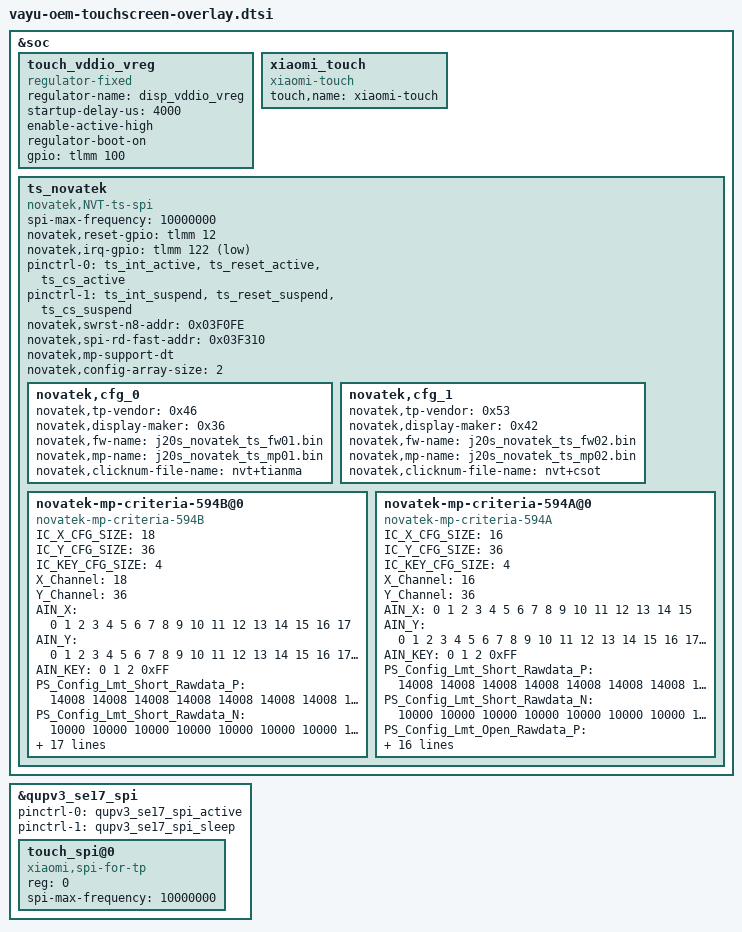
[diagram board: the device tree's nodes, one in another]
/* Copyright (c) 2021, The Linux Foundation. All rights reserved.
*  Copyright (c) 2021, Jebaitedneko <Jebaitedneko@gmail.com>.
*
* This program is free software; you can redistribute it and/or modify
* it under the terms of the GNU General Public License version 2 and
* only version 2 as published by the Free Software Foundation.
*
* This program is distributed in the hope that it will be useful,
* but WITHOUT ANY WARRANTY; without even the implied warranty of
* MERCHANTABILITY or FITNESS FOR A PARTICULAR PURPOSE.  See the
* GNU General Public License for more details.
*/

&soc {
	touch_vddio_vreg: touch_vddio_vreg {
		compatible = "regulator-fixed";
		regulator-name = "disp_vddio_vreg";
		startup-delay-us = <4000>;
		enable-active-high;
		regulator-boot-on;
		gpio = <&tlmm 100 0>;
	 };
	xiaomi_touch {
		compatible = "xiaomi-touch";
		status = "ok";
		touch,name = "xiaomi-touch";
	};

};

&qupv3_se17_spi {
		pinctrl-0 = <&qupv3_se17_spi_active>;
		pinctrl-1 = <&qupv3_se17_spi_sleep>;
		status = "ok";
		touch_spi@0 {
				compatible = "xiaomi,spi-for-tp";
				reg = <0>;
				status = "ok";
				spi-max-frequency = <10000000>;  //10M
		};
};

/* Novatek device tree node */
&soc {
	ts_novatek {
		compatible = "novatek,NVT-ts-spi";
		status = "ok";
		spi-max-frequency = <10000000>;  /*4800000,9600000,15000000,19200000 10M*/
		novatek,reset-gpio = <&tlmm 12 0x00>;
		novatek,irq-gpio = <&tlmm 122 0x2001>;
		pinctrl-names = "pmx_ts_active", "pmx_ts_suspend";
		pinctrl-0 = <&ts_int_active &ts_reset_active &ts_cs_active>;
		pinctrl-1 = <&ts_int_suspend &ts_reset_suspend &ts_cs_suspend>;
		/* 672 */
		/*novatek,swrst-n8-addr = <0x01F01A>;*/
		/* 672A */
		novatek,swrst-n8-addr = <0x03F0FE>;
		novatek,spi-rd-fast-addr = <0x03F310>;
		/* MP */
		novatek,mp-support-dt;
		novatek,config-array-size = <2>;
		novatek,cfg_0 {
			novatek,tp-vendor = <0x46>;
			novatek,display-maker = <0x36>;
			novatek,fw-name = "j20s_novatek_ts_fw01.bin";
			novatek,mp-name = "j20s_novatek_ts_mp01.bin";
			novatek,clicknum-file-name = "nvt+tianma";
		};
		novatek,cfg_1 {
			novatek,tp-vendor = <0x53>;
			novatek,display-maker = <0x42>;
			novatek,fw-name = "j20s_novatek_ts_fw02.bin";
			novatek,mp-name = "j20s_novatek_ts_mp02.bin";
			novatek,clicknum-file-name = "nvt+csot";
		};
		/* for Xiaomi J20S 672C CSOT6.67" module */
		novatek-mp-criteria-594B@0 {
			#address-cells = <1>;
			#size-cells = <0>;
			compatible = "novatek-mp-criteria-594B";
			/* MP Config */
			IC_X_CFG_SIZE = <18>;
			IC_Y_CFG_SIZE = <36>;
			IC_KEY_CFG_SIZE = <4>;
			X_Channel = <18>;
			Y_Channel = <36>;
			AIN_X = <0 1 2 3 4 5 6 7 8 9 10 11 12 13 14 15 16 17>;
			AIN_Y = <0 1 2 3 4 5 6 7 8 9 10 11 12 13 14 15 16 17
						18 19 20 21 22 23 24 25 26 27 28 29 30 31 32 33 34 35>;
			AIN_KEY = <0 1 2 0xFF>;
			/* MP Criteria */
			PS_Config_Lmt_Short_Rawdata_P = <
				14008 14008 14008 14008 14008 14008 14008 14008 14008 14008 14008 14008 14008 14008 14008 14008 14008 14008
				14008 14008 14008 14008 14008 14008 14008 14008 14008 14008 14008 14008 14008 14008 14008 14008 14008 14008
				14008 14008 14008 14008 14008 14008 14008 14008 14008 14008 14008 14008 14008 14008 14008 14008 14008 14008
				14008 14008 14008 14008 14008 14008 14008 14008 14008 14008 14008 14008 14008 14008 14008 14008 14008 14008
				14008 14008 14008 14008 14008 14008 14008 14008 14008 14008 14008 14008 14008 14008 14008 14008 14008 14008
				14008 14008 14008 14008 14008 14008 14008 14008 14008 14008 14008 14008 14008 14008 14008 14008 14008 14008
				14008 14008 14008 14008 14008 14008 14008 14008 14008 14008 14008 14008 14008 14008 14008 14008 14008 14008
				14008 14008 14008 14008 14008 14008 14008 14008 14008 14008 14008 14008 14008 14008 14008 14008 14008 14008
				14008 14008 14008 14008 14008 14008 14008 14008 14008 14008 14008 14008 14008 14008 14008 14008 14008 14008
				14008 14008 14008 14008 14008 14008 14008 14008 14008 14008 14008 14008 14008 14008 14008 14008 14008 14008
				14008 14008 14008 14008 14008 14008 14008 14008 14008 14008 14008 14008 14008 14008 14008 14008 14008 14008
				14008 14008 14008 14008 14008 14008 14008 14008 14008 14008 14008 14008 14008 14008 14008 14008 14008 14008
				14008 14008 14008 14008 14008 14008 14008 14008 14008 14008 14008 14008 14008 14008 14008 14008 14008 14008
				14008 14008 14008 14008 14008 14008 14008 14008 14008 14008 14008 14008 14008 14008 14008 14008 14008 14008
				14008 14008 14008 14008 14008 14008 14008 14008 14008 14008 14008 14008 14008 14008 14008 14008 14008 14008
				14008 14008 14008 14008 14008 14008 14008 14008 14008 14008 14008 14008 14008 14008 14008 14008 14008 14008
				14008 14008 14008 14008 14008 14008 14008 14008 14008 14008 14008 14008 14008 14008 14008 14008 14008 14008
				14008 14008 14008 14008 14008 14008 14008 14008 14008 14008 14008 14008 14008 14008 14008 14008 14008 14008
				14008 14008 14008 14008 14008 14008 14008 14008 14008 14008 14008 14008 14008 14008 14008 14008 14008 14008
				14008 14008 14008 14008 14008 14008 14008 14008 14008 14008 14008 14008 14008 14008 14008 14008 14008 14008
				14008 14008 14008 14008 14008 14008 14008 14008 14008 14008 14008 14008 14008 14008 14008 14008 14008 14008
				14008 14008 14008 14008 14008 14008 14008 14008 14008 14008 14008 14008 14008 14008 14008 14008 14008 14008
				14008 14008 14008 14008 14008 14008 14008 14008 14008 14008 14008 14008 14008 14008 14008 14008 14008 14008
				14008 14008 14008 14008 14008 14008 14008 14008 14008 14008 14008 14008 14008 14008 14008 14008 14008 14008
				14008 14008 14008 14008 14008 14008 14008 14008 14008 14008 14008 14008 14008 14008 14008 14008 14008 14008
				14008 14008 14008 14008 14008 14008 14008 14008 14008 14008 14008 14008 14008 14008 14008 14008 14008 14008
				14008 14008 14008 14008 14008 14008 14008 14008 14008 14008 14008 14008 14008 14008 14008 14008 14008 14008
				14008 14008 14008 14008 14008 14008 14008 14008 14008 14008 14008 14008 14008 14008 14008 14008 14008 14008
				14008 14008 14008 14008 14008 14008 14008 14008 14008 14008 14008 14008 14008 14008 14008 14008 14008 14008
				14008 14008 14008 14008 14008 14008 14008 14008 14008 14008 14008 14008 14008 14008 14008 14008 14008 14008
				14008 14008 14008 14008 14008 14008 14008 14008 14008 14008 14008 14008 14008 14008 14008 14008 14008 14008
				14008 14008 14008 14008 14008 14008 14008 14008 14008 14008 14008 14008 14008 14008 14008 14008 14008 14008
				14008 14008 14008 14008 14008 14008 14008 14008 14008 14008 14008 14008 14008 14008 14008 14008 14008 14008
				14008 14008 14008 14008 14008 14008 14008 14008 14008 14008 14008 14008 14008 14008 14008 14008 14008 14008
				14008 14008 14008 14008 14008 14008 14008 14008 14008 14008 14008 14008 14008 14008 14008 14008 14008 14008
				14008 14008 14008 14008 14008 14008 14008 14008 14008 14008 14008 14008 14008 14008 14008 14008 14008 14008
				14008 14008 14008>;

			PS_Config_Lmt_Short_Rawdata_N = <
				10000 10000 10000 10000 10000 10000 10000 10000 10000 10000 10000 10000 10000 10000 10000 10000 10000 10000
				10000 10000 10000 10000 10000 10000 10000 10000 10000 10000 10000 10000 10000 10000 10000 10000 10000 10000
				10000 10000 10000 10000 10000 10000 10000 10000 10000 10000 10000 10000 10000 10000 10000 10000 10000 10000
				10000 10000 10000 10000 10000 10000 10000 10000 10000 10000 10000 10000 10000 10000 10000 10000 10000 10000
				10000 10000 10000 10000 10000 10000 10000 10000 10000 10000 10000 10000 10000 10000 10000 10000 10000 10000
				10000 10000 10000 10000 10000 10000 10000 10000 10000 10000 10000 10000 10000 10000 10000 10000 10000 10000
				10000 10000 10000 10000 10000 10000 10000 10000 10000 10000 10000 10000 10000 10000 10000 10000 10000 10000
				10000 10000 10000 10000 10000 10000 10000 10000 10000 10000 10000 10000 10000 10000 10000 10000 10000 10000
				10000 10000 10000 10000 10000 10000 10000 10000 10000 10000 10000 10000 10000 10000 10000 10000 10000 10000
				10000 10000 10000 10000 10000 10000 10000 10000 10000 10000 10000 10000 10000 10000 10000 10000 10000 10000
				10000 10000 10000 10000 10000 10000 10000 10000 10000 10000 10000 10000 10000 10000 10000 10000 10000 10000
				10000 10000 10000 10000 10000 10000 10000 10000 10000 10000 10000 10000 10000 10000 10000 10000 10000 10000
				10000 10000 10000 10000 10000 10000 10000 10000 10000 10000 10000 10000 10000 10000 10000 10000 10000 10000
				10000 10000 10000 10000 10000 10000 10000 10000 10000 10000 10000 10000 10000 10000 10000 10000 10000 10000
				10000 10000 10000 10000 10000 10000 10000 10000 10000 10000 10000 10000 10000 10000 10000 10000 10000 10000
				10000 10000 10000 10000 10000 10000 10000 10000 10000 10000 10000 10000 10000 10000 10000 10000 10000 10000
				10000 10000 10000 10000 10000 10000 10000 10000 10000 10000 10000 10000 10000 10000 10000 10000 10000 10000
				10000 10000 10000 10000 10000 10000 10000 10000 10000 10000 10000 10000 10000 10000 10000 10000 10000 10000
				10000 10000 10000 10000 10000 10000 10000 10000 10000 10000 10000 10000 10000 10000 10000 10000 10000 10000
				10000 10000 10000 10000 10000 10000 10000 10000 10000 10000 10000 10000 10000 10000 10000 10000 10000 10000
				10000 10000 10000 10000 10000 10000 10000 10000 10000 10000 10000 10000 10000 10000 10000 10000 10000 10000
				10000 10000 10000 10000 10000 10000 10000 10000 10000 10000 10000 10000 10000 10000 10000 10000 10000 10000
				10000 10000 10000 10000 10000 10000 10000 10000 10000 10000 10000 10000 10000 10000 10000 10000 10000 10000
				10000 10000 10000 10000 10000 10000 10000 10000 10000 10000 10000 10000 10000 10000 10000 10000 10000 10000
				10000 10000 10000 10000 10000 10000 10000 10000 10000 10000 10000 10000 10000 10000 10000 10000 10000 10000
				10000 10000 10000 10000 10000 10000 10000 10000 10000 10000 10000 10000 10000 10000 10000 10000 10000 10000
				10000 10000 10000 10000 10000 10000 10000 10000 10000 10000 10000 10000 10000 10000 10000 10000 10000 10000
				10000 10000 10000 10000 10000 10000 10000 10000 10000 10000 10000 10000 10000 10000 10000 10000 10000 10000
				10000 10000 10000 10000 10000 10000 10000 10000 10000 10000 10000 10000 10000 10000 10000 10000 10000 10000
				10000 10000 10000 10000 10000 10000 10000 10000 10000 10000 10000 10000 10000 10000 10000 10000 10000 10000
				10000 10000 10000 10000 10000 10000 10000 10000 10000 10000 10000 10000 10000 10000 10000 10000 10000 10000
				10000 10000 10000 10000 10000 10000 10000 10000 10000 10000 10000 10000 10000 10000 10000 10000 10000 10000
				10000 10000 10000 10000 10000 10000 10000 10000 10000 10000 10000 10000 10000 10000 10000 10000 10000 10000
				10000 10000 10000 10000 10000 10000 10000 10000 10000 10000 10000 10000 10000 10000 10000 10000 10000 10000
				10000 10000 10000 10000 10000 10000 10000 10000 10000 10000 10000 10000 10000 10000 10000 10000 10000 10000
				10000 10000 10000 10000 10000 10000 10000 10000 10000 10000 10000 10000 10000 10000 10000 10000 10000 10000
				10000 10000 10000>;

			PS_Config_Lmt_Open_Rawdata_P = <
				5120 5120 5120 5120 5120 5120 5120 5120 5120 5120 5120 5120 5120 5120 5120 5120 5120 5120
				5120 5120 5120 5120 5120 5120 5120 5120 5120 5120 5120 5120 5120 5120 5120 5120 5120 5120
				5120 5120 5120 5120 5120 5120 5120 5120 5120 5120 5120 5120 5120 5120 5120 5120 5120 5120
				5120 5120 5120 5120 5120 5120 5120 5120 5120 5120 5120 5120 5120 5120 5120 5120 5120 5120
				5120 5120 5120 5120 5120 5120 5120 5120 5120 5120 5120 5120 5120 5120 5120 5120 5120 5120
				5120 5120 5120 5120 5120 5120 5120 5120 5120 5120 5120 5120 5120 5120 5120 5120 5120 5120
				5120 5120 5120 5120 5120 5120 5120 5120 5120 5120 5120 5120 5120 5120 5120 5120 5120 5120
				5120 5120 5120 5120 5120 5120 5120 5120 5120 5120 5120 5120 5120 5120 5120 5120 5120 5120
				5120 5120 5120 5120 5120 5120 5120 5120 5120 5120 5120 5120 5120 5120 5120 5120 5120 5120
				5120 5120 5120 5120 5120 5120 5120 5120 5120 5120 5120 5120 5120 5120 5120 5120 5120 5120
				5120 5120 5120 5120 5120 5120 5120 5120 5120 5120 5120 5120 5120 5120 5120 5120 5120 5120
				5120 5120 5120 5120 5120 5120 5120 5120 5120 5120 5120 5120 5120 5120 5120 5120 5120 5120
				5120 5120 5120 5120 5120 5120 5120 5120 5120 5120 5120 5120 5120 5120 5120 5120 5120 5120
				5120 5120 5120 5120 5120 5120 5120 5120 5120 5120 5120 5120 5120 5120 5120 5120 5120 5120
				5120 5120 5120 5120 5120 5120 5120 5120 5120 5120 5120 5120 5120 5120 5120 5120 5120 5120
				5120 5120 5120 5120 5120 5120 5120 5120 5120 5120 5120 5120 5120 5120 5120 5120 5120 5120
				5120 5120 5120 5120 5120 5120 5120 5120 5120 5120 5120 5120 5120 5120 5120 5120 5120 5120
				5120 5120 5120 5120 5120 5120 5120 5120 5120 5120 5120 5120 5120 5120 5120 5120 5120 5120
				5120 5120 5120 5120 5120 5120 5120 5120 5120 5120 5120 5120 5120 5120 5120 5120 5120 5120
				5120 5120 5120 5120 5120 5120 5120 5120 5120 5120 5120 5120 5120 5120 5120 5120 5120 5120
				5120 5120 5120 5120 5120 5120 5120 5120 5120 5120 5120 5120 5120 5120 5120 5120 5120 5120
				5120 5120 5120 5120 5120 5120 5120 5120 5120 5120 5120 5120 5120 5120 5120 5120 5120 5120
				5120 5120 5120 5120 5120 5120 5120 5120 5120 5120 5120 5120 5120 5120 5120 5120 5120 5120
				5120 5120 5120 5120 5120 5120 5120 5120 5120 5120 5120 5120 5120 5120 5120 5120 5120 5120
				5120 5120 5120 5120 5120 5120 5120 5120 5120 5120 5120 5120 5120 5120 5120 5120 5120 5120
				5120 5120 5120 5120 5120 5120 5120 5120 5120 5120 5120 5120 5120 5120 5120 5120 5120 5120
				5120 5120 5120 5120 5120 5120 5120 5120 5120 5120 5120 5120 5120 5120 5120 5120 5120 5120
				5120 5120 5120 5120 5120 5120 5120 5120 5120 5120 5120 5120 5120 5120 5120 5120 5120 5120
				5120 5120 5120 5120 5120 5120 5120 5120 5120 5120 5120 5120 5120 5120 5120 5120 5120 5120
				5120 5120 5120 5120 5120 5120 5120 5120 5120 5120 5120 5120 5120 5120 5120 5120 5120 5120
				5120 5120 5120 5120 5120 5120 5120 5120 5120 5120 5120 5120 5120 5120 5120 5120 5120 5120
				5120 5120 5120 5120 5120 5120 5120 5120 5120 5120 5120 5120 5120 5120 5120 5120 5120 5120
				5120 5120 5120 5120 5120 5120 5120 5120 5120 5120 5120 5120 5120 5120 5120 5120 5120 5120
				5120 5120 5120 5120 5120 5120 5120 5120 5120 5120 5120 5120 5120 5120 5120 5120 5120 5120
				5120 5120 5120 5120 5120 5120 5120 5120 5120 5120 5120 5120 5120 5120 5120 5120 5120 5120
				5120 5120 5120 5120 5120 5120 5120 5120 5120 5120 5120 5120 5120 5120 5120 5120 5120 5120
				5120 5120 5120>;

			PS_Config_Lmt_Open_Rawdata_N = <
				(-511) (-511) (-511) (-511) (-511) (-511) (-511) (-511) (-511) (-511) (-511) (-511) (-511) (-511) (-511) (-511) (-511) (-511)
				(-511) (-511) (-511) (-511) (-511) (-511) (-511) (-511) (-511) (-511) (-511) (-511) (-511) (-511) (-511) (-511) (-511) (-511)
				(-511) (-511) (-511) (-511) (-511) (-511) (-511) (-511) (-511) (-511) (-511) (-511) (-511) (-511) (-511) (-511) (-511) (-511)
				(-511) (-511) (-511) (-511) (-511) (-511) (-511) (-511) (-511) (-511) (-511) (-511) (-511) (-511) (-511) (-511) (-511) (-511)
				(-511) (-511) (-511) (-511) (-511) (-511) (-511) (-511) (-511) (-511) (-511) (-511) (-511) (-511) (-511) (-511) (-511) (-511)
				(-511) (-511) (-511) (-511) (-511) (-511) (-511) (-511) (-511) (-511) (-511) (-511) (-511) (-511) (-511) (-511) (-511) (-511)
				(-511) (-511) (-511) (-511) (-511) (-511) (-511) (-511) (-511) (-511) (-511) (-511) (-511) (-511) (-511) (-511) (-511) (-511)
				(-511) (-511) (-511) (-511) (-511) (-511) (-511) (-511) (-511) (-511) (-511) (-511) (-511) (-511) (-511) (-511) (-511) (-511)
				(-511) (-511) (-511) (-511) (-511) (-511) (-511) (-511) (-511) (-511) (-511) (-511) (-511) (-511) (-511) (-511) (-511) (-511)
				(-511) (-511) (-511) (-511) (-511) (-511) (-511) (-511) (-511) (-511) (-511) (-511) (-511) (-511) (-511) (-511) (-511) (-511)
				(-511) (-511) (-511) (-511) (-511) (-511) (-511) (-511) (-511) (-511) (-511) (-511) (-511) (-511) (-511) (-511) (-511) (-511)
				(-511) (-511) (-511) (-511) (-511) (-511) (-511) (-511) (-511) (-511) (-511) (-511) (-511) (-511) (-511) (-511) (-511) (-511)
				(-511) (-511) (-511) (-511) (-511) (-511) (-511) (-511) (-511) (-511) (-511) (-511) (-511) (-511) (-511) (-511) (-511) (-511)
				(-511) (-511) (-511) (-511) (-511) (-511) (-511) (-511) (-511) (-511) (-511) (-511) (-511) (-511) (-511) (-511) (-511) (-511)
				(-511) (-511) (-511) (-511) (-511) (-511) (-511) (-511) (-511) (-511) (-511) (-511) (-511) (-511) (-511) (-511) (-511) (-511)
				(-511) (-511) (-511) (-511) (-511) (-511) (-511) (-511) (-511) (-511) (-511) (-511) (-511) (-511) (-511) (-511) (-511) (-511)
				(-511) (-511) (-511) (-511) (-511) (-511) (-511) (-511) (-511) (-511) (-511) (-511) (-511) (-511) (-511) (-511) (-511) (-511)
				(-511) (-511) (-511) (-511) (-511) (-511) (-511) (-511) (-511) (-511) (-511) (-511) (-511) (-511) (-511) (-511) (-511) (-511)
				(-511) (-511) (-511) (-511) (-511) (-511) (-511) (-511) (-511) (-511) (-511) (-511) (-511) (-511) (-511) (-511) (-511) (-511)
				(-511) (-511) (-511) (-511) (-511) (-511) (-511) (-511) (-511) (-511) (-511) (-511) (-511) (-511) (-511) (-511) (-511) (-511)
				(-511) (-511) (-511) (-511) (-511) (-511) (-511) (-511) (-511) (-511) (-511) (-511) (-511) (-511) (-511) (-511) (-511) (-511)
				(-511) (-511) (-511) (-511) (-511) (-511) (-511) (-511) (-511) (-511) (-511) (-511) (-511) (-511) (-511) (-511) (-511) (-511)
				(-511) (-511) (-511) (-511) (-511) (-511) (-511) (-511) (-511) (-511) (-511) (-511) (-511) (-511) (-511) (-511) (-511) (-511)
				(-511) (-511) (-511) (-511) (-511) (-511) (-511) (-511) (-511) (-511) (-511) (-511) (-511) (-511) (-511) (-511) (-511) (-511)
				(-511) (-511) (-511) (-511) (-511) (-511) (-511) (-511) (-511) (-511) (-511) (-511) (-511) (-511) (-511) (-511) (-511) (-511)
				(-511) (-511) (-511) (-511) (-511) (-511) (-511) (-511) (-511) (-511) (-511) (-511) (-511) (-511) (-511) (-511) (-511) (-511)
				(-511) (-511) (-511) (-511) (-511) (-511) (-511) (-511) (-511) (-511) (-511) (-511) (-511) (-511) (-511) (-511) (-511) (-511)
				(-511) (-511) (-511) (-511) (-511) (-511) (-511) (-511) (-511) (-511) (-511) (-511) (-511) (-511) (-511) (-511) (-511) (-511)
				(-511) (-511) (-511) (-511) (-511) (-511) (-511) (-511) (-511) (-511) (-511) (-511) (-511) (-511) (-511) (-511) (-511) (-511)
				(-511) (-511) (-511) (-511) (-511) (-511) (-511) (-511) (-511) (-511) (-511) (-511) (-511) (-511) (-511) (-511) (-511) (-511)
				(-511) (-511) (-511) (-511) (-511) (-511) (-511) (-511) (-511) (-511) (-511) (-511) (-511) (-511) (-511) (-511) (-511) (-511)
				(-511) (-511) (-511) (-511) (-511) (-511) (-511) (-511) (-511) (-511) (-511) (-511) (-511) (-511) (-511) (-511) (-511) (-511)
				(-511) (-511) (-511) (-511) (-511) (-511) (-511) (-511) (-511) (-511) (-511) (-511) (-511) (-511) (-511) (-511) (-511) (-511)
				(-511) (-511) (-511) (-511) (-511) (-511) (-511) (-511) (-511) (-511) (-511) (-511) (-511) (-511) (-511) (-511) (-511) (-511)
				(-511) (-511) (-511) (-511) (-511) (-511) (-511) (-511) (-511) (-511) (-511) (-511) (-511) (-511) (-511) (-511) (-511) (-511)
				(-511) (-511) (-511) (-511) (-511) (-511) (-511) (-511) (-511) (-511) (-511) (-511) (-511) (-511) (-511) (-511) (-511) (-511)
				(-511) (-511) (-511)>;

			PS_Config_Lmt_FW_Rawdata_P = <
				3840 3840 3840 3840 3840 3840 3840 3840 3840 3840 3840 3840 3840 3840 3840 3840 3840 3840
				3840 3840 3840 3840 3840 3840 3840 3840 3840 3840 3840 3840 3840 3840 3840 3840 3840 3840
				3840 3840 3840 3840 3840 3840 3840 3840 3840 3840 3840 3840 3840 3840 3840 3840 3840 3840
				3840 3840 3840 3840 3840 3840 3840 3840 3840 3840 3840 3840 3840 3840 3840 3840 3840 3840
				3840 3840 3840 3840 3840 3840 3840 3840 3840 3840 3840 3840 3840 3840 3840 3840 3840 3840
				3840 3840 3840 3840 3840 3840 3840 3840 3840 3840 3840 3840 3840 3840 3840 3840 3840 3840
				3840 3840 3840 3840 3840 3840 3840 3840 3840 3840 3840 3840 3840 3840 3840 3840 3840 3840
				3840 3840 3840 3840 3840 3840 3840 3840 3840 3840 3840 3840 3840 3840 3840 3840 3840 3840
				3840 3840 3840 3840 3840 3840 3840 3840 3840 3840 3840 3840 3840 3840 3840 3840 3840 3840
				3840 3840 3840 3840 3840 3840 3840 3840 3840 3840 3840 3840 3840 3840 3840 3840 3840 3840
				3840 3840 3840 3840 3840 3840 3840 3840 3840 3840 3840 3840 3840 3840 3840 3840 3840 3840
				3840 3840 3840 3840 3840 3840 3840 3840 3840 3840 3840 3840 3840 3840 3840 3840 3840 3840
				3840 3840 3840 3840 3840 3840 3840 3840 3840 3840 3840 3840 3840 3840 3840 3840 3840 3840
				3840 3840 3840 3840 3840 3840 3840 3840 3840 3840 3840 3840 3840 3840 3840 3840 3840 3840
				3840 3840 3840 3840 3840 3840 3840 3840 3840 3840 3840 3840 3840 3840 3840 3840 3840 3840
				3840 3840 3840 3840 3840 3840 3840 3840 3840 3840 3840 3840 3840 3840 3840 3840 3840 3840
				3840 3840 3840 3840 3840 3840 3840 3840 3840 3840 3840 3840 3840 3840 3840 3840 3840 3840
				3840 3840 3840 3840 3840 3840 3840 3840 3840 3840 3840 3840 3840 3840 3840 3840 3840 3840
				3840 3840 3840 3840 3840 3840 3840 3840 3840 3840 3840 3840 3840 3840 3840 3840 3840 3840
				3840 3840 3840 3840 3840 3840 3840 3840 3840 3840 3840 3840 3840 3840 3840 3840 3840 3840
				3840 3840 3840 3840 3840 3840 3840 3840 3840 3840 3840 3840 3840 3840 3840 3840 3840 3840
				3840 3840 3840 3840 3840 3840 3840 3840 3840 3840 3840 3840 3840 3840 3840 3840 3840 3840
				3840 3840 3840 3840 3840 3840 3840 3840 3840 3840 3840 3840 3840 3840 3840 3840 3840 3840
				3840 3840 3840 3840 3840 3840 3840 3840 3840 3840 3840 3840 3840 3840 3840 3840 3840 3840
				3840 3840 3840 3840 3840 3840 3840 3840 3840 3840 3840 3840 3840 3840 3840 3840 3840 3840
				3840 3840 3840 3840 3840 3840 3840 3840 3840 3840 3840 3840 3840 3840 3840 3840 3840 3840
				3840 3840 3840 3840 3840 3840 3840 3840 3840 3840 3840 3840 3840 3840 3840 3840 3840 3840
				3840 3840 3840 3840 3840 3840 3840 3840 3840 3840 3840 3840 3840 3840 3840 3840 3840 3840
				3840 3840 3840 3840 3840 3840 3840 3840 3840 3840 3840 3840 3840 3840 3840 3840 3840 3840
				3840 3840 3840 3840 3840 3840 3840 3840 3840 3840 3840 3840 3840 3840 3840 3840 3840 3840
				3840 3840 3840 3840 3840 3840 3840 3840 3840 3840 3840 3840 3840 3840 3840 3840 3840 3840
				3840 3840 3840 3840 3840 3840 3840 3840 3840 3840 3840 3840 3840 3840 3840 3840 3840 3840
				3840 3840 3840 3840 3840 3840 3840 3840 3840 3840 3840 3840 3840 3840 3840 3840 3840 3840
				3840 3840 3840 3840 3840 3840 3840 3840 3840 3840 3840 3840 3840 3840 3840 3840 3840 3840
				3840 3840 3840 3840 3840 3840 3840 3840 3840 3840 3840 3840 3840 3840 3840 3840 3840 3840
				3840 3840 3840 3840 3840 3840 3840 3840 3840 3840 3840 3840 3840 3840 3840 3840 3840 3840
				3840 3840 3840>;

			PS_Config_Lmt_FW_Rawdata_N = <
				240 240 240 240 240 240 240 240 240 240 240 240 240 240 240 240 240 240
				240 240 240 240 240 240 240 240 240 240 240 240 240 240 240 240 240 240
				240 240 240 240 240 240 240 240 240 240 240 240 240 240 240 240 240 240
				240 240 240 240 240 240 240 240 240 240 240 240 240 240 240 240 240 240
				240 240 240 240 240 240 240 240 240 240 240 240 240 240 240 240 240 240
				240 240 240 240 240 240 240 240 240 240 240 240 240 240 240 240 240 240
				240 240 240 240 240 240 240 240 240 240 240 240 240 240 240 240 240 240
				240 240 240 240 240 240 240 240 240 240 240 240 240 240 240 240 240 240
				240 240 240 240 240 240 240 240 240 240 240 240 240 240 240 240 240 240
				240 240 240 240 240 240 240 240 240 240 240 240 240 240 240 240 240 240
				240 240 240 240 240 240 240 240 240 240 240 240 240 240 240 240 240 240
				240 240 240 240 240 240 240 240 240 240 240 240 240 240 240 240 240 240
				240 240 240 240 240 240 240 240 240 240 240 240 240 240 240 240 240 240
				240 240 240 240 240 240 240 240 240 240 240 240 240 240 240 240 240 240
				240 240 240 240 240 240 240 240 240 240 240 240 240 240 240 240 240 240
				240 240 240 240 240 240 240 240 240 240 240 240 240 240 240 240 240 240
				240 240 240 240 240 240 240 240 240 240 240 240 240 240 240 240 240 240
				240 240 240 240 240 240 240 240 240 240 240 240 240 240 240 240 240 240
				240 240 240 240 240 240 240 240 240 240 240 240 240 240 240 240 240 240
				240 240 240 240 240 240 240 240 240 240 240 240 240 240 240 240 240 240
				240 240 240 240 240 240 240 240 240 240 240 240 240 240 240 240 240 240
				240 240 240 240 240 240 240 240 240 240 240 240 240 240 240 240 240 240
				240 240 240 240 240 240 240 240 240 240 240 240 240 240 240 240 240 240
				240 240 240 240 240 240 240 240 240 240 240 240 240 240 240 240 240 240
				240 240 240 240 240 240 240 240 240 240 240 240 240 240 240 240 240 240
				240 240 240 240 240 240 240 240 240 240 240 240 240 240 240 240 240 240
				240 240 240 240 240 240 240 240 240 240 240 240 240 240 240 240 240 240
				240 240 240 240 240 240 240 240 240 240 240 240 240 240 240 240 240 240
				240 240 240 240 240 240 240 240 240 240 240 240 240 240 240 240 240 240
				240 240 240 240 240 240 240 240 240 240 240 240 240 240 240 240 240 240
				240 240 240 240 240 240 240 240 240 240 240 240 240 240 240 240 240 240
				240 240 240 240 240 240 240 240 240 240 240 240 240 240 240 240 240 240
				240 240 240 240 240 240 240 240 240 240 240 240 240 240 240 240 240 240
				240 240 240 240 240 240 240 240 240 240 240 240 240 240 240 240 240 240
				240 240 240 240 240 240 240 240 240 240 240 240 240 240 240 240 240 240
				240 240 240 240 240 240 240 240 240 240 240 240 240 240 240 240 240 240
				240 240 240>;

			PS_Config_Lmt_FW_CC_P = <
				314 314 314 314 314 314 314 314 314 314 314 314 314 314 314 314 314 314
				314 314 314 314 314 314 314 314 314 314 314 314 314 314 314 314 314 314
				314 314 314 314 314 314 314 314 314 314 314 314 314 314 314 314 314 314
				314 314 314 314 314 314 314 314 314 314 314 314 314 314 314 314 314 314
				314 314 314 314 314 314 314 314 314 314 314 314 314 314 314 314 314 314
				314 314 314 314 314 314 314 314 314 314 314 314 314 314 314 314 314 314
				314 314 314 314 314 314 314 314 314 314 314 314 314 314 314 314 314 314
				314 314 314 314 314 314 314 314 314 314 314 314 314 314 314 314 314 314
				314 314 314 314 314 314 314 314 314 314 314 314 314 314 314 314 314 314
				314 314 314 314 314 314 314 314 314 314 314 314 314 314 314 314 314 314
				314 314 314 314 314 314 314 314 314 314 314 314 314 314 314 314 314 314
				314 314 314 314 314 314 314 314 314 314 314 314 314 314 314 314 314 314
				314 314 314 314 314 314 314 314 314 314 314 314 314 314 314 314 314 314
				314 314 314 314 314 314 314 314 314 314 314 314 314 314 314 314 314 314
				314 314 314 314 314 314 314 314 314 314 314 314 314 314 314 314 314 314
				314 314 314 314 314 314 314 314 314 314 314 314 314 314 314 314 314 314
				314 314 314 314 314 314 314 314 314 314 314 314 314 314 314 314 314 314
				314 314 314 314 314 314 314 314 314 314 314 314 314 314 314 314 314 314
				314 314 314 314 314 314 314 314 314 314 314 314 314 314 314 314 314 314
				314 314 314 314 314 314 314 314 314 314 314 314 314 314 314 314 314 314
				314 314 314 314 314 314 314 314 314 314 314 314 314 314 314 314 314 314
				314 314 314 314 314 314 314 314 314 314 314 314 314 314 314 314 314 314
				314 314 314 314 314 314 314 314 314 314 314 314 314 314 314 314 314 314
				314 314 314 314 314 314 314 314 314 314 314 314 314 314 314 314 314 314
				314 314 314 314 314 314 314 314 314 314 314 314 314 314 314 314 314 314
				314 314 314 314 314 314 314 314 314 314 314 314 314 314 314 314 314 314
				314 314 314 314 314 314 314 314 314 314 314 314 314 314 314 314 314 314
				314 314 314 314 314 314 314 314 314 314 314 314 314 314 314 314 314 314
				314 314 314 314 314 314 314 314 314 314 314 314 314 314 314 314 314 314
				314 314 314 314 314 314 314 314 314 314 314 314 314 314 314 314 314 314
				314 314 314 314 314 314 314 314 314 314 314 314 314 314 314 314 314 314
				314 314 314 314 314 314 314 314 314 314 314 314 314 314 314 314 314 314
				314 314 314 314 314 314 314 314 314 314 314 314 314 314 314 314 314 314
				314 314 314 314 314 314 314 314 314 314 314 314 314 314 314 314 314 314
				314 314 314 314 314 314 314 314 314 314 314 314 314 314 314 314 314 314
				314 314 314 314 314 314 314 314 314 314 314 314 314 314 314 314 314 314
				314 314 314>;

			PS_Config_Lmt_FW_CC_N = <
				0 0 0 0 0 0 0 0 0 0 0 0 0 0 0 0 0 0
				0 0 0 0 0 0 0 0 0 0 0 0 0 0 0 0 0 0
				0 0 0 0 0 0 0 0 0 0 0 0 0 0 0 0 0 0
				0 0 0 0 0 0 0 0 0 0 0 0 0 0 0 0 0 0
				0 0 0 0 0 0 0 0 0 0 0 0 0 0 0 0 0 0
				0 0 0 0 0 0 0 0 0 0 0 0 0 0 0 0 0 0
				0 0 0 0 0 0 0 0 0 0 0 0 0 0 0 0 0 0
				0 0 0 0 0 0 0 0 0 0 0 0 0 0 0 0 0 0
				0 0 0 0 0 0 0 0 0 0 0 0 0 0 0 0 0 0
				0 0 0 0 0 0 0 0 0 0 0 0 0 0 0 0 0 0
				0 0 0 0 0 0 0 0 0 0 0 0 0 0 0 0 0 0
				0 0 0 0 0 0 0 0 0 0 0 0 0 0 0 0 0 0
				0 0 0 0 0 0 0 0 0 0 0 0 0 0 0 0 0 0
				0 0 0 0 0 0 0 0 0 0 0 0 0 0 0 0 0 0
				0 0 0 0 0 0 0 0 0 0 0 0 0 0 0 0 0 0
				0 0 0 0 0 0 0 0 0 0 0 0 0 0 0 0 0 0
				0 0 0 0 0 0 0 0 0 0 0 0 0 0 0 0 0 0
				0 0 0 0 0 0 0 0 0 0 0 0 0 0 0 0 0 0
				0 0 0 0 0 0 0 0 0 0 0 0 0 0 0 0 0 0
				0 0 0 0 0 0 0 0 0 0 0 0 0 0 0 0 0 0
				0 0 0 0 0 0 0 0 0 0 0 0 0 0 0 0 0 0
				0 0 0 0 0 0 0 0 0 0 0 0 0 0 0 0 0 0
				0 0 0 0 0 0 0 0 0 0 0 0 0 0 0 0 0 0
				0 0 0 0 0 0 0 0 0 0 0 0 0 0 0 0 0 0
				0 0 0 0 0 0 0 0 0 0 0 0 0 0 0 0 0 0
				0 0 0 0 0 0 0 0 0 0 0 0 0 0 0 0 0 0
				0 0 0 0 0 0 0 0 0 0 0 0 0 0 0 0 0 0
				0 0 0 0 0 0 0 0 0 0 0 0 0 0 0 0 0 0
				0 0 0 0 0 0 0 0 0 0 0 0 0 0 0 0 0 0
				0 0 0 0 0 0 0 0 0 0 0 0 0 0 0 0 0 0
				0 0 0 0 0 0 0 0 0 0 0 0 0 0 0 0 0 0
				0 0 0 0 0 0 0 0 0 0 0 0 0 0 0 0 0 0
				0 0 0 0 0 0 0 0 0 0 0 0 0 0 0 0 0 0
				0 0 0 0 0 0 0 0 0 0 0 0 0 0 0 0 0 0
				0 0 0 0 0 0 0 0 0 0 0 0 0 0 0 0 0 0
				0 0 0 0 0 0 0 0 0 0 0 0 0 0 0 0 0 0
				0 0 0>;

			PS_Config_Lmt_FW_Diff_P = <
				75 75 75 75 75 75 75 75 75 75 75 75 75 75 75 75 75 75
				75 75 75 75 75 75 75 75 75 75 75 75 75 75 75 75 75 75
				75 75 75 75 75 75 75 75 75 75 75 75 75 75 75 75 75 75
				75 75 75 75 75 75 75 75 75 75 75 75 75 75 75 75 75 75
				75 75 75 75 75 75 75 75 75 75 75 75 75 75 75 75 75 75
				75 75 75 75 75 75 75 75 75 75 75 75 75 75 75 75 75 75
				75 75 75 75 75 75 75 75 75 75 75 75 75 75 75 75 75 75
				75 75 75 75 75 75 75 75 75 75 75 75 75 75 75 75 75 75
				75 75 75 75 75 75 75 75 75 75 75 75 75 75 75 75 75 75
				75 75 75 75 75 75 75 75 75 75 75 75 75 75 75 75 75 75
				75 75 75 75 75 75 75 75 75 75 75 75 75 75 75 75 75 75
				75 75 75 75 75 75 75 75 75 75 75 75 75 75 75 75 75 75
				75 75 75 75 75 75 75 75 75 75 75 75 75 75 75 75 75 75
				75 75 75 75 75 75 75 75 75 75 75 75 75 75 75 75 75 75
				75 75 75 75 75 75 75 75 75 75 75 75 75 75 75 75 75 75
				75 75 75 75 75 75 75 75 75 75 75 75 75 75 75 75 75 75
				75 75 75 75 75 75 75 75 75 75 75 75 75 75 75 75 75 75
				75 75 75 75 75 75 75 75 75 75 75 75 75 75 75 75 75 75
				75 75 75 75 75 75 75 75 75 75 75 75 75 75 75 75 75 75
				75 75 75 75 75 75 75 75 75 75 75 75 75 75 75 75 75 75
				75 75 75 75 75 75 75 75 75 75 75 75 75 75 75 75 75 75
				75 75 75 75 75 75 75 75 75 75 75 75 75 75 75 75 75 75
				75 75 75 75 75 75 75 75 75 75 75 75 75 75 75 75 75 75
				75 75 75 75 75 75 75 75 75 75 75 75 75 75 75 75 75 75
				75 75 75 75 75 75 75 75 75 75 75 75 75 75 75 75 75 75
				75 75 75 75 75 75 75 75 75 75 75 75 75 75 75 75 75 75
				75 75 75 75 75 75 75 75 75 75 75 75 75 75 75 75 75 75
				75 75 75 75 75 75 75 75 75 75 75 75 75 75 75 75 75 75
				75 75 75 75 75 75 75 75 75 75 75 75 75 75 75 75 75 75
				75 75 75 75 75 75 75 75 75 75 75 75 75 75 75 75 75 75
				75 75 75 75 75 75 75 75 75 75 75 75 75 75 75 75 75 75
				75 75 75 75 75 75 75 75 75 75 75 75 75 75 75 75 75 75
				75 75 75 75 75 75 75 75 75 75 75 75 75 75 75 75 75 75
				75 75 75 75 75 75 75 75 75 75 75 75 75 75 75 75 75 75
				75 75 75 75 75 75 75 75 75 75 75 75 75 75 75 75 75 75
				75 75 75 75 75 75 75 75 75 75 75 75 75 75 75 75 75 75
				75 75 75>;

			PS_Config_Lmt_FW_Diff_N = <
				(-75) (-75) (-75) (-75) (-75) (-75) (-75) (-75) (-75) (-75) (-75) (-75) (-75) (-75) (-75) (-75) (-75) (-75)
				(-75) (-75) (-75) (-75) (-75) (-75) (-75) (-75) (-75) (-75) (-75) (-75) (-75) (-75) (-75) (-75) (-75) (-75)
				(-75) (-75) (-75) (-75) (-75) (-75) (-75) (-75) (-75) (-75) (-75) (-75) (-75) (-75) (-75) (-75) (-75) (-75)
				(-75) (-75) (-75) (-75) (-75) (-75) (-75) (-75) (-75) (-75) (-75) (-75) (-75) (-75) (-75) (-75) (-75) (-75)
				(-75) (-75) (-75) (-75) (-75) (-75) (-75) (-75) (-75) (-75) (-75) (-75) (-75) (-75) (-75) (-75) (-75) (-75)
				(-75) (-75) (-75) (-75) (-75) (-75) (-75) (-75) (-75) (-75) (-75) (-75) (-75) (-75) (-75) (-75) (-75) (-75)
				(-75) (-75) (-75) (-75) (-75) (-75) (-75) (-75) (-75) (-75) (-75) (-75) (-75) (-75) (-75) (-75) (-75) (-75)
				(-75) (-75) (-75) (-75) (-75) (-75) (-75) (-75) (-75) (-75) (-75) (-75) (-75) (-75) (-75) (-75) (-75) (-75)
				(-75) (-75) (-75) (-75) (-75) (-75) (-75) (-75) (-75) (-75) (-75) (-75) (-75) (-75) (-75) (-75) (-75) (-75)
				(-75) (-75) (-75) (-75) (-75) (-75) (-75) (-75) (-75) (-75) (-75) (-75) (-75) (-75) (-75) (-75) (-75) (-75)
				(-75) (-75) (-75) (-75) (-75) (-75) (-75) (-75) (-75) (-75) (-75) (-75) (-75) (-75) (-75) (-75) (-75) (-75)
				(-75) (-75) (-75) (-75) (-75) (-75) (-75) (-75) (-75) (-75) (-75) (-75) (-75) (-75) (-75) (-75) (-75) (-75)
				(-75) (-75) (-75) (-75) (-75) (-75) (-75) (-75) (-75) (-75) (-75) (-75) (-75) (-75) (-75) (-75) (-75) (-75)
				(-75) (-75) (-75) (-75) (-75) (-75) (-75) (-75) (-75) (-75) (-75) (-75) (-75) (-75) (-75) (-75) (-75) (-75)
				(-75) (-75) (-75) (-75) (-75) (-75) (-75) (-75) (-75) (-75) (-75) (-75) (-75) (-75) (-75) (-75) (-75) (-75)
				(-75) (-75) (-75) (-75) (-75) (-75) (-75) (-75) (-75) (-75) (-75) (-75) (-75) (-75) (-75) (-75) (-75) (-75)
				(-75) (-75) (-75) (-75) (-75) (-75) (-75) (-75) (-75) (-75) (-75) (-75) (-75) (-75) (-75) (-75) (-75) (-75)
				(-75) (-75) (-75) (-75) (-75) (-75) (-75) (-75) (-75) (-75) (-75) (-75) (-75) (-75) (-75) (-75) (-75) (-75)
				(-75) (-75) (-75) (-75) (-75) (-75) (-75) (-75) (-75) (-75) (-75) (-75) (-75) (-75) (-75) (-75) (-75) (-75)
				(-75) (-75) (-75) (-75) (-75) (-75) (-75) (-75) (-75) (-75) (-75) (-75) (-75) (-75) (-75) (-75) (-75) (-75)
				(-75) (-75) (-75) (-75) (-75) (-75) (-75) (-75) (-75) (-75) (-75) (-75) (-75) (-75) (-75) (-75) (-75) (-75)
				(-75) (-75) (-75) (-75) (-75) (-75) (-75) (-75) (-75) (-75) (-75) (-75) (-75) (-75) (-75) (-75) (-75) (-75)
				(-75) (-75) (-75) (-75) (-75) (-75) (-75) (-75) (-75) (-75) (-75) (-75) (-75) (-75) (-75) (-75) (-75) (-75)
				(-75) (-75) (-75) (-75) (-75) (-75) (-75) (-75) (-75) (-75) (-75) (-75) (-75) (-75) (-75) (-75) (-75) (-75)
				(-75) (-75) (-75) (-75) (-75) (-75) (-75) (-75) (-75) (-75) (-75) (-75) (-75) (-75) (-75) (-75) (-75) (-75)
				(-75) (-75) (-75) (-75) (-75) (-75) (-75) (-75) (-75) (-75) (-75) (-75) (-75) (-75) (-75) (-75) (-75) (-75)
				(-75) (-75) (-75) (-75) (-75) (-75) (-75) (-75) (-75) (-75) (-75) (-75) (-75) (-75) (-75) (-75) (-75) (-75)
				(-75) (-75) (-75) (-75) (-75) (-75) (-75) (-75) (-75) (-75) (-75) (-75) (-75) (-75) (-75) (-75) (-75) (-75)
				(-75) (-75) (-75) (-75) (-75) (-75) (-75) (-75) (-75) (-75) (-75) (-75) (-75) (-75) (-75) (-75) (-75) (-75)
				(-75) (-75) (-75) (-75) (-75) (-75) (-75) (-75) (-75) (-75) (-75) (-75) (-75) (-75) (-75) (-75) (-75) (-75)
				(-75) (-75) (-75) (-75) (-75) (-75) (-75) (-75) (-75) (-75) (-75) (-75) (-75) (-75) (-75) (-75) (-75) (-75)
				(-75) (-75) (-75) (-75) (-75) (-75) (-75) (-75) (-75) (-75) (-75) (-75) (-75) (-75) (-75) (-75) (-75) (-75)
				(-75) (-75) (-75) (-75) (-75) (-75) (-75) (-75) (-75) (-75) (-75) (-75) (-75) (-75) (-75) (-75) (-75) (-75)
				(-75) (-75) (-75) (-75) (-75) (-75) (-75) (-75) (-75) (-75) (-75) (-75) (-75) (-75) (-75) (-75) (-75) (-75)
				(-75) (-75) (-75) (-75) (-75) (-75) (-75) (-75) (-75) (-75) (-75) (-75) (-75) (-75) (-75) (-75) (-75) (-75)
				(-75) (-75) (-75) (-75) (-75) (-75) (-75) (-75) (-75) (-75) (-75) (-75) (-75) (-75) (-75) (-75) (-75) (-75)
				(-75) (-75) (-75)>;

			PS_Config_Diff_Test_Frame = <50>;
		};

		/* for Xiaomi J20S 672C TM6.67" module */
		novatek-mp-criteria-594A@0 {
			#address-cells = <1>;
			#size-cells = <0>;
			compatible = "novatek-mp-criteria-594A";

			/* MP Config */
			IC_X_CFG_SIZE = <16>;
			IC_Y_CFG_SIZE = <36>;
			IC_KEY_CFG_SIZE = <4>;
			X_Channel = <16>;
			Y_Channel = <36>;
			AIN_X = <0 1 2 3 4 5 6 7 8 9 10 11 12 13 14 15>;
			AIN_Y = <0 1 2 3 4 5 6 7 8 9 10 11 12 13 14 15 16 17
						18 19 20 21 22 23 24 25 26 27 28 29 30 31 32 33 34 35>;
			AIN_KEY = <0 1 2 0xFF>;

			/* MP Criteria */
			PS_Config_Lmt_Short_Rawdata_P = <
				14008 14008 14008 14008 14008 14008 14008 14008 14008 14008 14008 14008 14008 14008 14008 14008
				14008 14008 14008 14008 14008 14008 14008 14008 14008 14008 14008 14008 14008 14008 14008 14008
				14008 14008 14008 14008 14008 14008 14008 14008 14008 14008 14008 14008 14008 14008 14008 14008
				14008 14008 14008 14008 14008 14008 14008 14008 14008 14008 14008 14008 14008 14008 14008 14008
				14008 14008 14008 14008 14008 14008 14008 14008 14008 14008 14008 14008 14008 14008 14008 14008
				14008 14008 14008 14008 14008 14008 14008 14008 14008 14008 14008 14008 14008 14008 14008 14008
				14008 14008 14008 14008 14008 14008 14008 14008 14008 14008 14008 14008 14008 14008 14008 14008
				14008 14008 14008 14008 14008 14008 14008 14008 14008 14008 14008 14008 14008 14008 14008 14008
				14008 14008 14008 14008 14008 14008 14008 14008 14008 14008 14008 14008 14008 14008 14008 14008
				14008 14008 14008 14008 14008 14008 14008 14008 14008 14008 14008 14008 14008 14008 14008 14008
				14008 14008 14008 14008 14008 14008 14008 14008 14008 14008 14008 14008 14008 14008 14008 14008
				14008 14008 14008 14008 14008 14008 14008 14008 14008 14008 14008 14008 14008 14008 14008 14008
				14008 14008 14008 14008 14008 14008 14008 14008 14008 14008 14008 14008 14008 14008 14008 14008
				14008 14008 14008 14008 14008 14008 14008 14008 14008 14008 14008 14008 14008 14008 14008 14008
				14008 14008 14008 14008 14008 14008 14008 14008 14008 14008 14008 14008 14008 14008 14008 14008
				14008 14008 14008 14008 14008 14008 14008 14008 14008 14008 14008 14008 14008 14008 14008 14008
				14008 14008 14008 14008 14008 14008 14008 14008 14008 14008 14008 14008 14008 14008 14008 14008
				14008 14008 14008 14008 14008 14008 14008 14008 14008 14008 14008 14008 14008 14008 14008 14008
				14008 14008 14008 14008 14008 14008 14008 14008 14008 14008 14008 14008 14008 14008 14008 14008
				14008 14008 14008 14008 14008 14008 14008 14008 14008 14008 14008 14008 14008 14008 14008 14008
				14008 14008 14008 14008 14008 14008 14008 14008 14008 14008 14008 14008 14008 14008 14008 14008
				14008 14008 14008 14008 14008 14008 14008 14008 14008 14008 14008 14008 14008 14008 14008 14008
				14008 14008 14008 14008 14008 14008 14008 14008 14008 14008 14008 14008 14008 14008 14008 14008
				14008 14008 14008 14008 14008 14008 14008 14008 14008 14008 14008 14008 14008 14008 14008 14008
				14008 14008 14008 14008 14008 14008 14008 14008 14008 14008 14008 14008 14008 14008 14008 14008
				14008 14008 14008 14008 14008 14008 14008 14008 14008 14008 14008 14008 14008 14008 14008 14008
				14008 14008 14008 14008 14008 14008 14008 14008 14008 14008 14008 14008 14008 14008 14008 14008
				14008 14008 14008 14008 14008 14008 14008 14008 14008 14008 14008 14008 14008 14008 14008 14008
				14008 14008 14008 14008 14008 14008 14008 14008 14008 14008 14008 14008 14008 14008 14008 14008
				14008 14008 14008 14008 14008 14008 14008 14008 14008 14008 14008 14008 14008 14008 14008 14008
				14008 14008 14008 14008 14008 14008 14008 14008 14008 14008 14008 14008 14008 14008 14008 14008
				14008 14008 14008 14008 14008 14008 14008 14008 14008 14008 14008 14008 14008 14008 14008 14008
				14008 14008 14008 14008 14008 14008 14008 14008 14008 14008 14008 14008 14008 14008 14008 14008
				14008 14008 14008 14008 14008 14008 14008 14008 14008 14008 14008 14008 14008 14008 14008 14008
				14008 14008 14008 14008 14008 14008 14008 14008 14008 14008 14008 14008 14008 14008 14008 14008
				14008 14008 14008 14008 14008 14008 14008 14008 14008 14008 14008 14008 14008 14008 14008 14008
				14008 14008 14008>;

			PS_Config_Lmt_Short_Rawdata_N = <
				10000 10000 10000 10000 10000 10000 10000 10000 10000 10000 10000 10000 10000 10000 10000 10000
				10000 10000 10000 10000 10000 10000 10000 10000 10000 10000 10000 10000 10000 10000 10000 10000
				10000 10000 10000 10000 10000 10000 10000 10000 10000 10000 10000 10000 10000 10000 10000 10000
				10000 10000 10000 10000 10000 10000 10000 10000 10000 10000 10000 10000 10000 10000 10000 10000
				10000 10000 10000 10000 10000 10000 10000 10000 10000 10000 10000 10000 10000 10000 10000 10000
				10000 10000 10000 10000 10000 10000 10000 10000 10000 10000 10000 10000 10000 10000 10000 10000
				10000 10000 10000 10000 10000 10000 10000 10000 10000 10000 10000 10000 10000 10000 10000 10000
				10000 10000 10000 10000 10000 10000 10000 10000 10000 10000 10000 10000 10000 10000 10000 10000
				10000 10000 10000 10000 10000 10000 10000 10000 10000 10000 10000 10000 10000 10000 10000 10000
				10000 10000 10000 10000 10000 10000 10000 10000 10000 10000 10000 10000 10000 10000 10000 10000
				10000 10000 10000 10000 10000 10000 10000 10000 10000 10000 10000 10000 10000 10000 10000 10000
				10000 10000 10000 10000 10000 10000 10000 10000 10000 10000 10000 10000 10000 10000 10000 10000
				10000 10000 10000 10000 10000 10000 10000 10000 10000 10000 10000 10000 10000 10000 10000 10000
				10000 10000 10000 10000 10000 10000 10000 10000 10000 10000 10000 10000 10000 10000 10000 10000
				10000 10000 10000 10000 10000 10000 10000 10000 10000 10000 10000 10000 10000 10000 10000 10000
				10000 10000 10000 10000 10000 10000 10000 10000 10000 10000 10000 10000 10000 10000 10000 10000
				10000 10000 10000 10000 10000 10000 10000 10000 10000 10000 10000 10000 10000 10000 10000 10000
				10000 10000 10000 10000 10000 10000 10000 10000 10000 10000 10000 10000 10000 10000 10000 10000
				10000 10000 10000 10000 10000 10000 10000 10000 10000 10000 10000 10000 10000 10000 10000 10000
				10000 10000 10000 10000 10000 10000 10000 10000 10000 10000 10000 10000 10000 10000 10000 10000
				10000 10000 10000 10000 10000 10000 10000 10000 10000 10000 10000 10000 10000 10000 10000 10000
				10000 10000 10000 10000 10000 10000 10000 10000 10000 10000 10000 10000 10000 10000 10000 10000
				10000 10000 10000 10000 10000 10000 10000 10000 10000 10000 10000 10000 10000 10000 10000 10000
				10000 10000 10000 10000 10000 10000 10000 10000 10000 10000 10000 10000 10000 10000 10000 10000
				10000 10000 10000 10000 10000 10000 10000 10000 10000 10000 10000 10000 10000 10000 10000 10000
				10000 10000 10000 10000 10000 10000 10000 10000 10000 10000 10000 10000 10000 10000 10000 10000
				10000 10000 10000 10000 10000 10000 10000 10000 10000 10000 10000 10000 10000 10000 10000 10000
				10000 10000 10000 10000 10000 10000 10000 10000 10000 10000 10000 10000 10000 10000 10000 10000
				10000 10000 10000 10000 10000 10000 10000 10000 10000 10000 10000 10000 10000 10000 10000 10000
				10000 10000 10000 10000 10000 10000 10000 10000 10000 10000 10000 10000 10000 10000 10000 10000
				10000 10000 10000 10000 10000 10000 10000 10000 10000 10000 10000 10000 10000 10000 10000 10000
				10000 10000 10000 10000 10000 10000 10000 10000 10000 10000 10000 10000 10000 10000 10000 10000
				10000 10000 10000 10000 10000 10000 10000 10000 10000 10000 10000 10000 10000 10000 10000 10000
				10000 10000 10000 10000 10000 10000 10000 10000 10000 10000 10000 10000 10000 10000 10000 10000
				10000 10000 10000 10000 10000 10000 10000 10000 10000 10000 10000 10000 10000 10000 10000 10000
				10000 10000 10000 10000 10000 10000 10000 10000 10000 10000 10000 10000 10000 10000 10000 10000
				10000 10000 10000>;

			PS_Config_Lmt_Open_Rawdata_P = <
				5120 5120 5120 5120 5120 5120 5120 5120 5120 5120 5120 5120 5120 5120 5120 5120
				5120 5120 5120 5120 5120 5120 5120 5120 5120 5120 5120 5120 5120 5120 5120 5120
				5120 5120 5120 5120 5120 5120 5120 5120 5120 5120 5120 5120 5120 5120 5120 5120
				5120 5120 5120 5120 5120 5120 5120 5120 5120 5120 5120 5120 5120 5120 5120 5120
				5120 5120 5120 5120 5120 5120 5120 5120 5120 5120 5120 5120 5120 5120 5120 5120
				5120 5120 5120 5120 5120 5120 5120 5120 5120 5120 5120 5120 5120 5120 5120 5120
				5120 5120 5120 5120 5120 5120 5120 5120 5120 5120 5120 5120 5120 5120 5120 5120
				5120 5120 5120 5120 5120 5120 5120 5120 5120 5120 5120 5120 5120 5120 5120 5120
				5120 5120 5120 5120 5120 5120 5120 5120 5120 5120 5120 5120 5120 5120 5120 5120
				5120 5120 5120 5120 5120 5120 5120 5120 5120 5120 5120 5120 5120 5120 5120 5120
				5120 5120 5120 5120 5120 5120 5120 5120 5120 5120 5120 5120 5120 5120 5120 5120
				5120 5120 5120 5120 5120 5120 5120 5120 5120 5120 5120 5120 5120 5120 5120 5120
				5120 5120 5120 5120 5120 5120 5120 5120 5120 5120 5120 5120 5120 5120 5120 5120
				5120 5120 5120 5120 5120 5120 5120 5120 5120 5120 5120 5120 5120 5120 5120 5120
				5120 5120 5120 5120 5120 5120 5120 5120 5120 5120 5120 5120 5120 5120 5120 5120
				5120 5120 5120 5120 5120 5120 5120 5120 5120 5120 5120 5120 5120 5120 5120 5120
				5120 5120 5120 5120 5120 5120 5120 5120 5120 5120 5120 5120 5120 5120 5120 5120
				5120 5120 5120 5120 5120 5120 5120 5120 5120 5120 5120 5120 5120 5120 5120 5120
				5120 5120 5120 5120 5120 5120 5120 5120 5120 5120 5120 5120 5120 5120 5120 5120
				5120 5120 5120 5120 5120 5120 5120 5120 5120 5120 5120 5120 5120 5120 5120 5120
				5120 5120 5120 5120 5120 5120 5120 5120 5120 5120 5120 5120 5120 5120 5120 5120
				5120 5120 5120 5120 5120 5120 5120 5120 5120 5120 5120 5120 5120 5120 5120 5120
				5120 5120 5120 5120 5120 5120 5120 5120 5120 5120 5120 5120 5120 5120 5120 5120
				5120 5120 5120 5120 5120 5120 5120 5120 5120 5120 5120 5120 5120 5120 5120 5120
				5120 5120 5120 5120 5120 5120 5120 5120 5120 5120 5120 5120 5120 5120 5120 5120
				5120 5120 5120 5120 5120 5120 5120 5120 5120 5120 5120 5120 5120 5120 5120 5120
				5120 5120 5120 5120 5120 5120 5120 5120 5120 5120 5120 5120 5120 5120 5120 5120
				5120 5120 5120 5120 5120 5120 5120 5120 5120 5120 5120 5120 5120 5120 5120 5120
				5120 5120 5120 5120 5120 5120 5120 5120 5120 5120 5120 5120 5120 5120 5120 5120
				5120 5120 5120 5120 5120 5120 5120 5120 5120 5120 5120 5120 5120 5120 5120 5120
				5120 5120 5120 5120 5120 5120 5120 5120 5120 5120 5120 5120 5120 5120 5120 5120
				5120 5120 5120 5120 5120 5120 5120 5120 5120 5120 5120 5120 5120 5120 5120 5120
				5120 5120 5120 5120 5120 5120 5120 5120 5120 5120 5120 5120 5120 5120 5120 5120
				5120 5120 5120 5120 5120 5120 5120 5120 5120 5120 5120 5120 5120 5120 5120 5120
				5120 5120 5120 5120 5120 5120 5120 5120 5120 5120 5120 5120 5120 5120 5120 5120
				5120 5120 5120 5120 5120 5120 5120 5120 5120 5120 5120 5120 5120 5120 5120 5120
				5120 5120 5120>;

			PS_Config_Lmt_Open_Rawdata_N = <
				(-511) (-511) (-511) (-511) (-511) (-511) (-511) (-511) (-511) (-511) (-511) (-511) (-511) (-511) (-511) (-511)
				(-511) (-511) (-511) (-511) (-511) (-511) (-511) (-511) (-511) (-511) (-511) (-511) (-511) (-511) (-511) (-511)
				(-511) (-511) (-511) (-511) (-511) (-511) (-511) (-511) (-511) (-511) (-511) (-511) (-511) (-511) (-511) (-511)
				(-511) (-511) (-511) (-511) (-511) (-511) (-511) (-511) (-511) (-511) (-511) (-511) (-511) (-511) (-511) (-511)
				(-511) (-511) (-511) (-511) (-511) (-511) (-511) (-511) (-511) (-511) (-511) (-511) (-511) (-511) (-511) (-511)
				(-511) (-511) (-511) (-511) (-511) (-511) (-511) (-511) (-511) (-511) (-511) (-511) (-511) (-511) (-511) (-511)
				(-511) (-511) (-511) (-511) (-511) (-511) (-511) (-511) (-511) (-511) (-511) (-511) (-511) (-511) (-511) (-511)
				(-511) (-511) (-511) (-511) (-511) (-511) (-511) (-511) (-511) (-511) (-511) (-511) (-511) (-511) (-511) (-511)
				(-511) (-511) (-511) (-511) (-511) (-511) (-511) (-511) (-511) (-511) (-511) (-511) (-511) (-511) (-511) (-511)
				(-511) (-511) (-511) (-511) (-511) (-511) (-511) (-511) (-511) (-511) (-511) (-511) (-511) (-511) (-511) (-511)
				(-511) (-511) (-511) (-511) (-511) (-511) (-511) (-511) (-511) (-511) (-511) (-511) (-511) (-511) (-511) (-511)
				(-511) (-511) (-511) (-511) (-511) (-511) (-511) (-511) (-511) (-511) (-511) (-511) (-511) (-511) (-511) (-511)
				(-511) (-511) (-511) (-511) (-511) (-511) (-511) (-511) (-511) (-511) (-511) (-511) (-511) (-511) (-511) (-511)
				(-511) (-511) (-511) (-511) (-511) (-511) (-511) (-511) (-511) (-511) (-511) (-511) (-511) (-511) (-511) (-511)
				(-511) (-511) (-511) (-511) (-511) (-511) (-511) (-511) (-511) (-511) (-511) (-511) (-511) (-511) (-511) (-511)
				(-511) (-511) (-511) (-511) (-511) (-511) (-511) (-511) (-511) (-511) (-511) (-511) (-511) (-511) (-511) (-511)
				(-511) (-511) (-511) (-511) (-511) (-511) (-511) (-511) (-511) (-511) (-511) (-511) (-511) (-511) (-511) (-511)
				(-511) (-511) (-511) (-511) (-511) (-511) (-511) (-511) (-511) (-511) (-511) (-511) (-511) (-511) (-511) (-511)
				(-511) (-511) (-511) (-511) (-511) (-511) (-511) (-511) (-511) (-511) (-511) (-511) (-511) (-511) (-511) (-511)
				(-511) (-511) (-511) (-511) (-511) (-511) (-511) (-511) (-511) (-511) (-511) (-511) (-511) (-511) (-511) (-511)
				(-511) (-511) (-511) (-511) (-511) (-511) (-511) (-511) (-511) (-511) (-511) (-511) (-511) (-511) (-511) (-511)
				(-511) (-511) (-511) (-511) (-511) (-511) (-511) (-511) (-511) (-511) (-511) (-511) (-511) (-511) (-511) (-511)
				(-511) (-511) (-511) (-511) (-511) (-511) (-511) (-511) (-511) (-511) (-511) (-511) (-511) (-511) (-511) (-511)
				(-511) (-511) (-511) (-511) (-511) (-511) (-511) (-511) (-511) (-511) (-511) (-511) (-511) (-511) (-511) (-511)
				(-511) (-511) (-511) (-511) (-511) (-511) (-511) (-511) (-511) (-511) (-511) (-511) (-511) (-511) (-511) (-511)
				(-511) (-511) (-511) (-511) (-511) (-511) (-511) (-511) (-511) (-511) (-511) (-511) (-511) (-511) (-511) (-511)
				(-511) (-511) (-511) (-511) (-511) (-511) (-511) (-511) (-511) (-511) (-511) (-511) (-511) (-511) (-511) (-511)
				(-511) (-511) (-511) (-511) (-511) (-511) (-511) (-511) (-511) (-511) (-511) (-511) (-511) (-511) (-511) (-511)
				(-511) (-511) (-511) (-511) (-511) (-511) (-511) (-511) (-511) (-511) (-511) (-511) (-511) (-511) (-511) (-511)
				(-511) (-511) (-511) (-511) (-511) (-511) (-511) (-511) (-511) (-511) (-511) (-511) (-511) (-511) (-511) (-511)
				(-511) (-511) (-511) (-511) (-511) (-511) (-511) (-511) (-511) (-511) (-511) (-511) (-511) (-511) (-511) (-511)
				(-511) (-511) (-511) (-511) (-511) (-511) (-511) (-511) (-511) (-511) (-511) (-511) (-511) (-511) (-511) (-511)
				(-511) (-511) (-511) (-511) (-511) (-511) (-511) (-511) (-511) (-511) (-511) (-511) (-511) (-511) (-511) (-511)
				(-511) (-511) (-511) (-511) (-511) (-511) (-511) (-511) (-511) (-511) (-511) (-511) (-511) (-511) (-511) (-511)
				(-511) (-511) (-511) (-511) (-511) (-511) (-511) (-511) (-511) (-511) (-511) (-511) (-511) (-511) (-511) (-511)
				(-511) (-511) (-511) (-511) (-511) (-511) (-511) (-511) (-511) (-511) (-511) (-511) (-511) (-511) (-511) (-511)
				(-511) (-511) (-511)>;

			PS_Config_Lmt_FW_Rawdata_P = <
				3840 3840 3840 3840 3840 3840 3840 3840 3840 3840 3840 3840 3840 3840 3840 3840
				3840 3840 3840 3840 3840 3840 3840 3840 3840 3840 3840 3840 3840 3840 3840 3840
				3840 3840 3840 3840 3840 3840 3840 3840 3840 3840 3840 3840 3840 3840 3840 3840
				3840 3840 3840 3840 3840 3840 3840 3840 3840 3840 3840 3840 3840 3840 3840 3840
				3840 3840 3840 3840 3840 3840 3840 3840 3840 3840 3840 3840 3840 3840 3840 3840
				3840 3840 3840 3840 3840 3840 3840 3840 3840 3840 3840 3840 3840 3840 3840 3840
				3840 3840 3840 3840 3840 3840 3840 3840 3840 3840 3840 3840 3840 3840 3840 3840
				3840 3840 3840 3840 3840 3840 3840 3840 3840 3840 3840 3840 3840 3840 3840 3840
				3840 3840 3840 3840 3840 3840 3840 3840 3840 3840 3840 3840 3840 3840 3840 3840
				3840 3840 3840 3840 3840 3840 3840 3840 3840 3840 3840 3840 3840 3840 3840 3840
				3840 3840 3840 3840 3840 3840 3840 3840 3840 3840 3840 3840 3840 3840 3840 3840
				3840 3840 3840 3840 3840 3840 3840 3840 3840 3840 3840 3840 3840 3840 3840 3840
				3840 3840 3840 3840 3840 3840 3840 3840 3840 3840 3840 3840 3840 3840 3840 3840
				3840 3840 3840 3840 3840 3840 3840 3840 3840 3840 3840 3840 3840 3840 3840 3840
				3840 3840 3840 3840 3840 3840 3840 3840 3840 3840 3840 3840 3840 3840 3840 3840
				3840 3840 3840 3840 3840 3840 3840 3840 3840 3840 3840 3840 3840 3840 3840 3840
				3840 3840 3840 3840 3840 3840 3840 3840 3840 3840 3840 3840 3840 3840 3840 3840
				3840 3840 3840 3840 3840 3840 3840 3840 3840 3840 3840 3840 3840 3840 3840 3840
				3840 3840 3840 3840 3840 3840 3840 3840 3840 3840 3840 3840 3840 3840 3840 3840
				3840 3840 3840 3840 3840 3840 3840 3840 3840 3840 3840 3840 3840 3840 3840 3840
				3840 3840 3840 3840 3840 3840 3840 3840 3840 3840 3840 3840 3840 3840 3840 3840
				3840 3840 3840 3840 3840 3840 3840 3840 3840 3840 3840 3840 3840 3840 3840 3840
				3840 3840 3840 3840 3840 3840 3840 3840 3840 3840 3840 3840 3840 3840 3840 3840
				3840 3840 3840 3840 3840 3840 3840 3840 3840 3840 3840 3840 3840 3840 3840 3840
				3840 3840 3840 3840 3840 3840 3840 3840 3840 3840 3840 3840 3840 3840 3840 3840
				3840 3840 3840 3840 3840 3840 3840 3840 3840 3840 3840 3840 3840 3840 3840 3840
				3840 3840 3840 3840 3840 3840 3840 3840 3840 3840 3840 3840 3840 3840 3840 3840
				3840 3840 3840 3840 3840 3840 3840 3840 3840 3840 3840 3840 3840 3840 3840 3840
				3840 3840 3840 3840 3840 3840 3840 3840 3840 3840 3840 3840 3840 3840 3840 3840
				3840 3840 3840 3840 3840 3840 3840 3840 3840 3840 3840 3840 3840 3840 3840 3840
				3840 3840 3840 3840 3840 3840 3840 3840 3840 3840 3840 3840 3840 3840 3840 3840
				3840 3840 3840 3840 3840 3840 3840 3840 3840 3840 3840 3840 3840 3840 3840 3840
				3840 3840 3840 3840 3840 3840 3840 3840 3840 3840 3840 3840 3840 3840 3840 3840
				3840 3840 3840 3840 3840 3840 3840 3840 3840 3840 3840 3840 3840 3840 3840 3840
				3840 3840 3840 3840 3840 3840 3840 3840 3840 3840 3840 3840 3840 3840 3840 3840
				3840 3840 3840 3840 3840 3840 3840 3840 3840 3840 3840 3840 3840 3840 3840 3840
				3840 3840 3840>;

			PS_Config_Lmt_FW_Rawdata_N = <
				240 240 240 240 240 240 240 240 240 240 240 240 240 240 240 240
				240 240 240 240 240 240 240 240 240 240 240 240 240 240 240 240
				240 240 240 240 240 240 240 240 240 240 240 240 240 240 240 240
				240 240 240 240 240 240 240 240 240 240 240 240 240 240 240 240
				240 240 240 240 240 240 240 240 240 240 240 240 240 240 240 240
				240 240 240 240 240 240 240 240 240 240 240 240 240 240 240 240
				240 240 240 240 240 240 240 240 240 240 240 240 240 240 240 240
				240 240 240 240 240 240 240 240 240 240 240 240 240 240 240 240
				240 240 240 240 240 240 240 240 240 240 240 240 240 240 240 240
				240 240 240 240 240 240 240 240 240 240 240 240 240 240 240 240
				240 240 240 240 240 240 240 240 240 240 240 240 240 240 240 240
				240 240 240 240 240 240 240 240 240 240 240 240 240 240 240 240
				240 240 240 240 240 240 240 240 240 240 240 240 240 240 240 240
				240 240 240 240 240 240 240 240 240 240 240 240 240 240 240 240
				240 240 240 240 240 240 240 240 240 240 240 240 240 240 240 240
				240 240 240 240 240 240 240 240 240 240 240 240 240 240 240 240
				240 240 240 240 240 240 240 240 240 240 240 240 240 240 240 240
				240 240 240 240 240 240 240 240 240 240 240 240 240 240 240 240
				240 240 240 240 240 240 240 240 240 240 240 240 240 240 240 240
				240 240 240 240 240 240 240 240 240 240 240 240 240 240 240 240
				240 240 240 240 240 240 240 240 240 240 240 240 240 240 240 240
				240 240 240 240 240 240 240 240 240 240 240 240 240 240 240 240
				240 240 240 240 240 240 240 240 240 240 240 240 240 240 240 240
				240 240 240 240 240 240 240 240 240 240 240 240 240 240 240 240
				240 240 240 240 240 240 240 240 240 240 240 240 240 240 240 240
				240 240 240 240 240 240 240 240 240 240 240 240 240 240 240 240
				240 240 240 240 240 240 240 240 240 240 240 240 240 240 240 240
				240 240 240 240 240 240 240 240 240 240 240 240 240 240 240 240
				240 240 240 240 240 240 240 240 240 240 240 240 240 240 240 240
				240 240 240 240 240 240 240 240 240 240 240 240 240 240 240 240
				240 240 240 240 240 240 240 240 240 240 240 240 240 240 240 240
				240 240 240 240 240 240 240 240 240 240 240 240 240 240 240 240
				240 240 240 240 240 240 240 240 240 240 240 240 240 240 240 240
				240 240 240 240 240 240 240 240 240 240 240 240 240 240 240 240
				240 240 240 240 240 240 240 240 240 240 240 240 240 240 240 240
				240 240 240 240 240 240 240 240 240 240 240 240 240 240 240 240
				240 240 240>;

			PS_Config_Lmt_FW_CC_P = <
				314 314 314 314 314 314 314 314 314 314 314 314 314 314 314 314
				314 314 314 314 314 314 314 314 314 314 314 314 314 314 314 314
				314 314 314 314 314 314 314 314 314 314 314 314 314 314 314 314
				314 314 314 314 314 314 314 314 314 314 314 314 314 314 314 314
				314 314 314 314 314 314 314 314 314 314 314 314 314 314 314 314
				314 314 314 314 314 314 314 314 314 314 314 314 314 314 314 314
				314 314 314 314 314 314 314 314 314 314 314 314 314 314 314 314
				314 314 314 314 314 314 314 314 314 314 314 314 314 314 314 314
				314 314 314 314 314 314 314 314 314 314 314 314 314 314 314 314
				314 314 314 314 314 314 314 314 314 314 314 314 314 314 314 314
				314 314 314 314 314 314 314 314 314 314 314 314 314 314 314 314
				314 314 314 314 314 314 314 314 314 314 314 314 314 314 314 314
				314 314 314 314 314 314 314 314 314 314 314 314 314 314 314 314
				314 314 314 314 314 314 314 314 314 314 314 314 314 314 314 314
				314 314 314 314 314 314 314 314 314 314 314 314 314 314 314 314
				314 314 314 314 314 314 314 314 314 314 314 314 314 314 314 314
				314 314 314 314 314 314 314 314 314 314 314 314 314 314 314 314
				314 314 314 314 314 314 314 314 314 314 314 314 314 314 314 314
				314 314 314 314 314 314 314 314 314 314 314 314 314 314 314 314
				314 314 314 314 314 314 314 314 314 314 314 314 314 314 314 314
				314 314 314 314 314 314 314 314 314 314 314 314 314 314 314 314
				314 314 314 314 314 314 314 314 314 314 314 314 314 314 314 314
				314 314 314 314 314 314 314 314 314 314 314 314 314 314 314 314
				314 314 314 314 314 314 314 314 314 314 314 314 314 314 314 314
				314 314 314 314 314 314 314 314 314 314 314 314 314 314 314 314
				314 314 314 314 314 314 314 314 314 314 314 314 314 314 314 314
				314 314 314 314 314 314 314 314 314 314 314 314 314 314 314 314
				314 314 314 314 314 314 314 314 314 314 314 314 314 314 314 314
				314 314 314 314 314 314 314 314 314 314 314 314 314 314 314 314
				314 314 314 314 314 314 314 314 314 314 314 314 314 314 314 314
				314 314 314 314 314 314 314 314 314 314 314 314 314 314 314 314
				314 314 314 314 314 314 314 314 314 314 314 314 314 314 314 314
				314 314 314 314 314 314 314 314 314 314 314 314 314 314 314 314
				314 314 314 314 314 314 314 314 314 314 314 314 314 314 314 314
				314 314 314 314 314 314 314 314 314 314 314 314 314 314 314 314
				314 314 314 314 314 314 314 314 314 314 314 314 314 314 314 314
				314 314 314>;

			PS_Config_Lmt_FW_CC_N = <
				0 0 0 0 0 0 0 0 0 0 0 0 0 0 0 0
				0 0 0 0 0 0 0 0 0 0 0 0 0 0 0 0
				0 0 0 0 0 0 0 0 0 0 0 0 0 0 0 0
				0 0 0 0 0 0 0 0 0 0 0 0 0 0 0 0
				0 0 0 0 0 0 0 0 0 0 0 0 0 0 0 0
				0 0 0 0 0 0 0 0 0 0 0 0 0 0 0 0
				0 0 0 0 0 0 0 0 0 0 0 0 0 0 0 0
				0 0 0 0 0 0 0 0 0 0 0 0 0 0 0 0
				0 0 0 0 0 0 0 0 0 0 0 0 0 0 0 0
				0 0 0 0 0 0 0 0 0 0 0 0 0 0 0 0
				0 0 0 0 0 0 0 0 0 0 0 0 0 0 0 0
				0 0 0 0 0 0 0 0 0 0 0 0 0 0 0 0
				0 0 0 0 0 0 0 0 0 0 0 0 0 0 0 0
				0 0 0 0 0 0 0 0 0 0 0 0 0 0 0 0
				0 0 0 0 0 0 0 0 0 0 0 0 0 0 0 0
				0 0 0 0 0 0 0 0 0 0 0 0 0 0 0 0
				0 0 0 0 0 0 0 0 0 0 0 0 0 0 0 0
				0 0 0 0 0 0 0 0 0 0 0 0 0 0 0 0
				0 0 0 0 0 0 0 0 0 0 0 0 0 0 0 0
				0 0 0 0 0 0 0 0 0 0 0 0 0 0 0 0
				0 0 0 0 0 0 0 0 0 0 0 0 0 0 0 0
				0 0 0 0 0 0 0 0 0 0 0 0 0 0 0 0
				0 0 0 0 0 0 0 0 0 0 0 0 0 0 0 0
				0 0 0 0 0 0 0 0 0 0 0 0 0 0 0 0
				0 0 0 0 0 0 0 0 0 0 0 0 0 0 0 0
				0 0 0 0 0 0 0 0 0 0 0 0 0 0 0 0
				0 0 0 0 0 0 0 0 0 0 0 0 0 0 0 0
				0 0 0 0 0 0 0 0 0 0 0 0 0 0 0 0
				0 0 0 0 0 0 0 0 0 0 0 0 0 0 0 0
				0 0 0 0 0 0 0 0 0 0 0 0 0 0 0 0
				0 0 0 0 0 0 0 0 0 0 0 0 0 0 0 0
				0 0 0 0 0 0 0 0 0 0 0 0 0 0 0 0
				0 0 0 0 0 0 0 0 0 0 0 0 0 0 0 0
				0 0 0 0 0 0 0 0 0 0 0 0 0 0 0 0
				0 0 0 0 0 0 0 0 0 0 0 0 0 0 0 0
				0 0 0 0 0 0 0 0 0 0 0 0 0 0 0 0
				0 0 0>;

			PS_Config_Lmt_FW_Diff_P = <
				75 75 75 75 75 75 75 75 75 75 75 75 75 75 75 75
				75 75 75 75 75 75 75 75 75 75 75 75 75 75 75 75
				75 75 75 75 75 75 75 75 75 75 75 75 75 75 75 75
				75 75 75 75 75 75 75 75 75 75 75 75 75 75 75 75
				75 75 75 75 75 75 75 75 75 75 75 75 75 75 75 75
				75 75 75 75 75 75 75 75 75 75 75 75 75 75 75 75
				75 75 75 75 75 75 75 75 75 75 75 75 75 75 75 75
				75 75 75 75 75 75 75 75 75 75 75 75 75 75 75 75
				75 75 75 75 75 75 75 75 75 75 75 75 75 75 75 75
				75 75 75 75 75 75 75 75 75 75 75 75 75 75 75 75
				75 75 75 75 75 75 75 75 75 75 75 75 75 75 75 75
				75 75 75 75 75 75 75 75 75 75 75 75 75 75 75 75
				75 75 75 75 75 75 75 75 75 75 75 75 75 75 75 75
				75 75 75 75 75 75 75 75 75 75 75 75 75 75 75 75
				75 75 75 75 75 75 75 75 75 75 75 75 75 75 75 75
				75 75 75 75 75 75 75 75 75 75 75 75 75 75 75 75
				75 75 75 75 75 75 75 75 75 75 75 75 75 75 75 75
				75 75 75 75 75 75 75 75 75 75 75 75 75 75 75 75
				75 75 75 75 75 75 75 75 75 75 75 75 75 75 75 75
				75 75 75 75 75 75 75 75 75 75 75 75 75 75 75 75
				75 75 75 75 75 75 75 75 75 75 75 75 75 75 75 75
				75 75 75 75 75 75 75 75 75 75 75 75 75 75 75 75
				75 75 75 75 75 75 75 75 75 75 75 75 75 75 75 75
				75 75 75 75 75 75 75 75 75 75 75 75 75 75 75 75
				75 75 75 75 75 75 75 75 75 75 75 75 75 75 75 75
				75 75 75 75 75 75 75 75 75 75 75 75 75 75 75 75
				75 75 75 75 75 75 75 75 75 75 75 75 75 75 75 75
				75 75 75 75 75 75 75 75 75 75 75 75 75 75 75 75
				75 75 75 75 75 75 75 75 75 75 75 75 75 75 75 75
				75 75 75 75 75 75 75 75 75 75 75 75 75 75 75 75
				75 75 75 75 75 75 75 75 75 75 75 75 75 75 75 75
				75 75 75 75 75 75 75 75 75 75 75 75 75 75 75 75
				75 75 75 75 75 75 75 75 75 75 75 75 75 75 75 75
				75 75 75 75 75 75 75 75 75 75 75 75 75 75 75 75
				75 75 75 75 75 75 75 75 75 75 75 75 75 75 75 75
				75 75 75 75 75 75 75 75 75 75 75 75 75 75 75 75
				75 75 75>;

			PS_Config_Lmt_FW_Diff_N = <
				(-75) (-75) (-75) (-75) (-75) (-75) (-75) (-75) (-75) (-75) (-75) (-75) (-75) (-75) (-75) (-75)
				(-75) (-75) (-75) (-75) (-75) (-75) (-75) (-75) (-75) (-75) (-75) (-75) (-75) (-75) (-75) (-75)
				(-75) (-75) (-75) (-75) (-75) (-75) (-75) (-75) (-75) (-75) (-75) (-75) (-75) (-75) (-75) (-75)
				(-75) (-75) (-75) (-75) (-75) (-75) (-75) (-75) (-75) (-75) (-75) (-75) (-75) (-75) (-75) (-75)
				(-75) (-75) (-75) (-75) (-75) (-75) (-75) (-75) (-75) (-75) (-75) (-75) (-75) (-75) (-75) (-75)
				(-75) (-75) (-75) (-75) (-75) (-75) (-75) (-75) (-75) (-75) (-75) (-75) (-75) (-75) (-75) (-75)
				(-75) (-75) (-75) (-75) (-75) (-75) (-75) (-75) (-75) (-75) (-75) (-75) (-75) (-75) (-75) (-75)
				(-75) (-75) (-75) (-75) (-75) (-75) (-75) (-75) (-75) (-75) (-75) (-75) (-75) (-75) (-75) (-75)
				(-75) (-75) (-75) (-75) (-75) (-75) (-75) (-75) (-75) (-75) (-75) (-75) (-75) (-75) (-75) (-75)
				(-75) (-75) (-75) (-75) (-75) (-75) (-75) (-75) (-75) (-75) (-75) (-75) (-75) (-75) (-75) (-75)
				(-75) (-75) (-75) (-75) (-75) (-75) (-75) (-75) (-75) (-75) (-75) (-75) (-75) (-75) (-75) (-75)
				(-75) (-75) (-75) (-75) (-75) (-75) (-75) (-75) (-75) (-75) (-75) (-75) (-75) (-75) (-75) (-75)
				(-75) (-75) (-75) (-75) (-75) (-75) (-75) (-75) (-75) (-75) (-75) (-75) (-75) (-75) (-75) (-75)
				(-75) (-75) (-75) (-75) (-75) (-75) (-75) (-75) (-75) (-75) (-75) (-75) (-75) (-75) (-75) (-75)
				(-75) (-75) (-75) (-75) (-75) (-75) (-75) (-75) (-75) (-75) (-75) (-75) (-75) (-75) (-75) (-75)
				(-75) (-75) (-75) (-75) (-75) (-75) (-75) (-75) (-75) (-75) (-75) (-75) (-75) (-75) (-75) (-75)
				(-75) (-75) (-75) (-75) (-75) (-75) (-75) (-75) (-75) (-75) (-75) (-75) (-75) (-75) (-75) (-75)
				(-75) (-75) (-75) (-75) (-75) (-75) (-75) (-75) (-75) (-75) (-75) (-75) (-75) (-75) (-75) (-75)
				(-75) (-75) (-75) (-75) (-75) (-75) (-75) (-75) (-75) (-75) (-75) (-75) (-75) (-75) (-75) (-75)
				(-75) (-75) (-75) (-75) (-75) (-75) (-75) (-75) (-75) (-75) (-75) (-75) (-75) (-75) (-75) (-75)
				(-75) (-75) (-75) (-75) (-75) (-75) (-75) (-75) (-75) (-75) (-75) (-75) (-75) (-75) (-75) (-75)
				(-75) (-75) (-75) (-75) (-75) (-75) (-75) (-75) (-75) (-75) (-75) (-75) (-75) (-75) (-75) (-75)
				(-75) (-75) (-75) (-75) (-75) (-75) (-75) (-75) (-75) (-75) (-75) (-75) (-75) (-75) (-75) (-75)
				(-75) (-75) (-75) (-75) (-75) (-75) (-75) (-75) (-75) (-75) (-75) (-75) (-75) (-75) (-75) (-75)
				(-75) (-75) (-75) (-75) (-75) (-75) (-75) (-75) (-75) (-75) (-75) (-75) (-75) (-75) (-75) (-75)
				(-75) (-75) (-75) (-75) (-75) (-75) (-75) (-75) (-75) (-75) (-75) (-75) (-75) (-75) (-75) (-75)
				(-75) (-75) (-75) (-75) (-75) (-75) (-75) (-75) (-75) (-75) (-75) (-75) (-75) (-75) (-75) (-75)
				(-75) (-75) (-75) (-75) (-75) (-75) (-75) (-75) (-75) (-75) (-75) (-75) (-75) (-75) (-75) (-75)
				(-75) (-75) (-75) (-75) (-75) (-75) (-75) (-75) (-75) (-75) (-75) (-75) (-75) (-75) (-75) (-75)
				(-75) (-75) (-75) (-75) (-75) (-75) (-75) (-75) (-75) (-75) (-75) (-75) (-75) (-75) (-75) (-75)
				(-75) (-75) (-75) (-75) (-75) (-75) (-75) (-75) (-75) (-75) (-75) (-75) (-75) (-75) (-75) (-75)
				(-75) (-75) (-75) (-75) (-75) (-75) (-75) (-75) (-75) (-75) (-75) (-75) (-75) (-75) (-75) (-75)
				(-75) (-75) (-75) (-75) (-75) (-75) (-75) (-75) (-75) (-75) (-75) (-75) (-75) (-75) (-75) (-75)
				(-75) (-75) (-75) (-75) (-75) (-75) (-75) (-75) (-75) (-75) (-75) (-75) (-75) (-75) (-75) (-75)
				(-75) (-75) (-75) (-75) (-75) (-75) (-75) (-75) (-75) (-75) (-75) (-75) (-75) (-75) (-75) (-75)
				(-75) (-75) (-75) (-75) (-75) (-75) (-75) (-75) (-75) (-75) (-75) (-75) (-75) (-75) (-75) (-75)
				(-75) (-75) (-75)>;

			PS_Config_Diff_Test_Frame = <50>;
		};
	};
};
